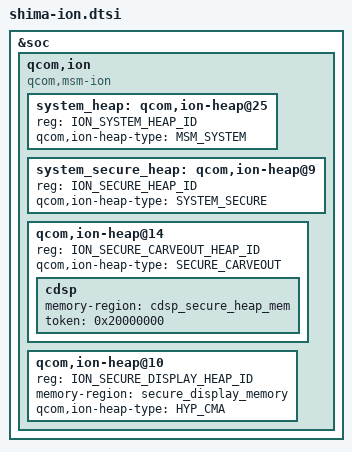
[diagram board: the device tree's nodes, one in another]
#include <dt-bindings/arm/msm/msm_ion_ids.h>

&soc {
	qcom,ion {
		compatible = "qcom,msm-ion";
		#address-cells = <1>;
		#size-cells = <0>;

		system_heap: qcom,ion-heap@25 {
			reg = <ION_SYSTEM_HEAP_ID>;
			qcom,ion-heap-type = "MSM_SYSTEM";
		};

		system_secure_heap: qcom,ion-heap@9 {
			reg = <ION_SECURE_HEAP_ID>;
			qcom,ion-heap-type = "SYSTEM_SECURE";
		};

		qcom,ion-heap@14 { /* SECURE CARVEOUT HEAP */
			reg = <ION_SECURE_CARVEOUT_HEAP_ID>;
			qcom,ion-heap-type = "SECURE_CARVEOUT";
			cdsp {
					memory-region = <&cdsp_secure_heap_mem>;
					token = <0x20000000>;
			};
		};

		qcom,ion-heap@10 { /* SECURE DISPLAY HEAP */
			reg = <ION_SECURE_DISPLAY_HEAP_ID>;
			memory-region = <&secure_display_memory>;
			qcom,ion-heap-type = "HYP_CMA";
		};
	};
};
